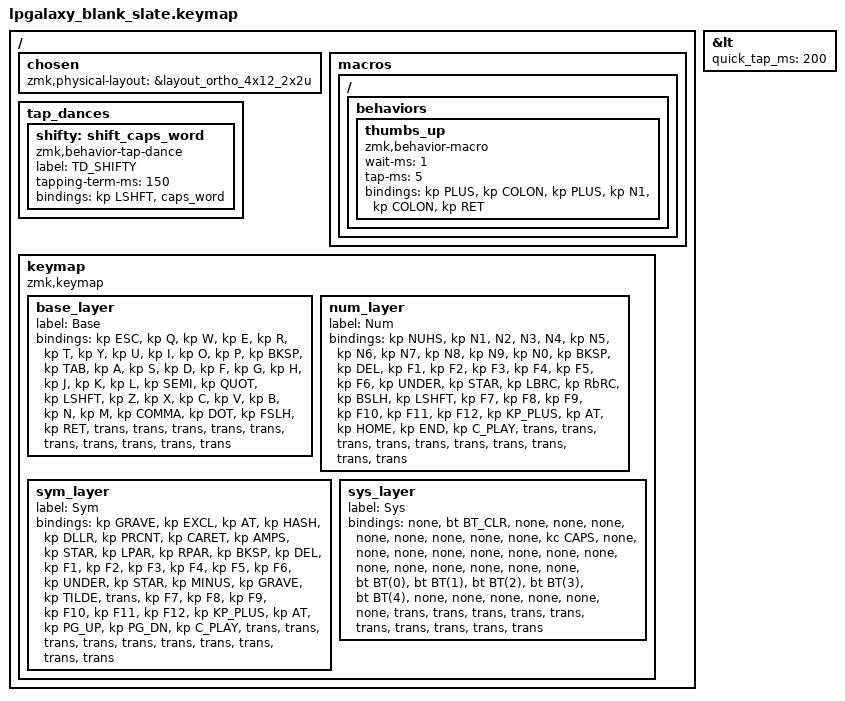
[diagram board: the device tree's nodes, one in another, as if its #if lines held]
/*
 * Copyright (c) 2022 Pete Johanson
 *
 * SPDX-License-Identifier: MIT
 */

#include <behaviors.dtsi>
#include <dt-bindings/zmk/keys.h>
#include <dt-bindings/zmk/bt.h>
#include <dt-bindings/zmk/outputs.h>

#define QWERTY_BASE 1

// #define TBLE_ORTHO   1
#define TBLE_MIT     1
// #define TBLE_DUAL_2U 1

#define NUM_L 1
#define SYM_L 2
#define SYS_L 3

// Using layer taps on thumbs, having quick tap as well helps w/ repeating space/backspace
&lt { quick_tap_ms = <200>; };

#define BT(n) BT_SEL n

/ {
    chosen {
       zmk,physical-layout =
#ifdef TBLE_DUAL_2U
                       &layout_ortho_4x12_2x2u;
#elif defined(TBLE_MIT)
                       &layout_ortho_4x12_1x2u;
#else
                       &layout_ortho_4x12_all1u;
#endif
    };

    macros {
      ZMK_MACRO(thumbs_up,
		wait-ms = <1>;
		tap-ms = <5>;
                bindings = <&kp PLUS &kp COLON &kp PLUS &kp N1 &kp COLON &kp RET>;
		)
    };
    
    tap_dances {
    	shifty: shift_caps_word {
		compatible = "zmk,behavior-tap-dance";
		label = "TD_SHIFTY";
		#binding-cells = <0>;
		tapping-term-ms = <150>;
		bindings = <&kp LSHFT>, <&caps_word>;
	};
    };

    keymap {
        compatible = "zmk,keymap";

        base_layer {
            label = "Base";
            bindings = <
#ifdef QWERTY_BASE
 &kp ESC     &kp Q      &kp W     &kp E     &kp R     &kp T     &kp Y     &kp U     &kp I       &kp O     &kp P      &kp BKSP
 &kp TAB     &kp A      &kp S     &kp D     &kp F     &kp G     &kp H     &kp J     &kp K       &kp L     &kp SEMI   &kp QUOT
 &kp LSHFT   &kp Z      &kp X     &kp C     &kp V     &kp B     &kp N     &kp M     &kp COMMA   &kp DOT   &kp FSLH   &kp RET
#else
 &kp ESC     &kp Q      &kp W     &kp F     &kp P     &kp B     &kp J     &kp L     &kp U       &kp Y     &kp QUOT   &kp BKSP
 &kp TAB     &kp A      &kp R     &kp S     &kp T     &kp G     &kp M     &kp N     &kp E       &kp I     &kp O      &kp QUOT
 &kp LSHFT   &kp Z      &kp X     &kp C     &kp D     &kp V     &kp K     &kp H     &kp COMMA   &kp DOT   &kp SEMI   &kp RET
#endif
#ifdef TBLE_DUAL_2U
 &trans     &trans     &trans     &trans                 &trans       &trans                   &trans     &trans     &trans     &trans
#elif defined(TBLE_MIT)
 &kp LCTRL  &kp RALT   &kp LGUI   &kp LALT   &mo NUM_L         &trans            &mo SYM_L     &kp LEFT   &kp DOWN   &kp UP     &kp RIGHT
#else
 &trans     &trans     &trans     &trans     &trans      &trans       &trans     &trans        &trans     &trans     &trans     &trans
#endif
            >;
        };

        num_layer {
            label = "Num";
            bindings = <
 &kp NUHS   &kp N1      &N2        &N3        &N4        &kp N5      &kp N6       &kp N7       &kp N8     &kp N9     &kp N0     &kp BKSP
 &kp DEL    &kp F1      &kp F2     &kp F3     &kp F4     &kp F5      &kp F6       &kp UNDER    &kp STAR   &kp LBRC   &kp RbRC   &kp BSLH
 &kp LSHFT  &kp F7      &kp F8     &kp F9     &kp F10    &kp F11     &kp F12      &kp KP_PLUS  &kp AT     &kp HOME   &kp END    &kp C_PLAY
#ifdef TBLE_DUAL_2U
 &trans     &trans     &trans     &trans                 &trans      &trans                    &trans     &trans     &trans       &trans
#elif defined(TBLE_MIT)
 &kp LCTRL  &kp RALT   &kp LGUI   &kp LALT    &mo NUM_L        &trans             &mo SYM_L    &kp LT     &kp GT     &kp C_PREV   &kp C_NEXT
#else
 &trans     &trans     &trans     &trans      &trans     &trans      &trans       &trans       &trans     &trans     &trans       &trans
#endif
            >;
        };

        sym_layer {
            label = "Sym";
            bindings = <
 &kp GRAVE  &kp EXCL    &kp AT     &kp HASH   &kp DLLR   &kp PRCNT   &kp CARET    &kp AMPS      &kp STAR    &kp LPAR    &kp RPAR   &kp BKSP
 &kp DEL    &kp F1      &kp F2     &kp F3     &kp F4     &kp F5      &kp F6       &kp UNDER     &kp STAR    &kp MINUS   &kp GRAVE  &kp TILDE
 &trans     &kp F7      &kp F8     &kp F9     &kp F10    &kp F11     &kp F12      &kp KP_PLUS   &kp AT      &kp PG_UP   &kp PG_DN  &kp C_PLAY
#ifdef TBLE_DUAL_2U
 &trans      &trans     &trans     &trans                &trans      &trans                     &trans      &trans      &trans       &trans
#elif defined(TBLE_MIT)
 &kp LCTRL   &kp RALT   &kp LGUI   &kp LALT   &mo NUM_L        &trans             &mo SYM_L     &kp PIPE    &kp NUBS    &kp C_PREV   &kp C_NEXT
#else
 &trans      &trans     &trans     &trans     &trans     &trans      &trans       &trans        &trans      &trans      &trans       &trans
#endif
            >;
        };

        sys_layer {
            label = "Sys";
            bindings = <
 &none     &bt BT_CLR     &none       &none       &none       &none       &none     &none     &none      &none     &kc CAPS   &none
 &none     &none          &none       &none       &none       &none       &none     &none     &none      &none     &none      &none
 &none     &bt BT(0)      &bt BT(1)   &bt BT(2)   &bt BT(3)   &bt BT(4)   &none     &none     &none      &none     &none      &none
#ifdef TBLE_DUAL_2U
 &trans    &trans     &trans     &trans                 &trans      &trans                      &trans     &trans    &trans    &trans
#elif defined(TBLE_MIT)
 &none     &none      &none      &none      &mo NUM_L         &none             &mo SYM_L       &none      &none     &none     &none
#else
 &trans    &trans     &trans     &trans     &trans      &trans      &trans      &trans          &trans     &trans    &trans    &trans
#endif
            >;
        };


    };
};

